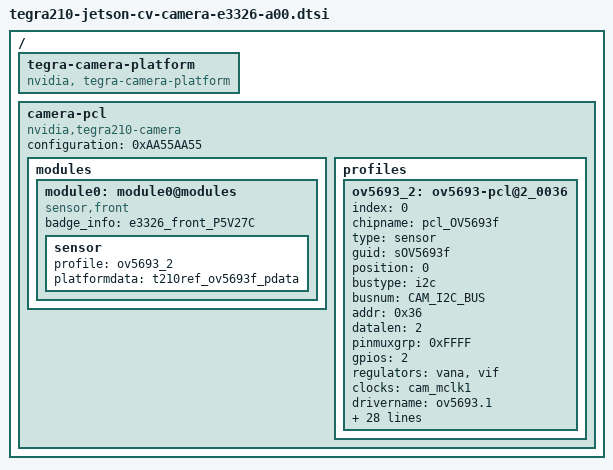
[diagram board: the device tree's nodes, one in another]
/*
 * Copyright (c) 2015, NVIDIA CORPORATION.  All rights reserved.
 *
 * This program is free software; you can redistribute it and/or modify
 * it under the terms of the GNU General Public License as published by
 * the Free Software Foundation; either version 2 of the License, or
 * (at your option) any later version.
 *
 * This program is distributed in the hope that it will be useful, but WITHOUT
 * ANY WARRANTY; without even the implied warranty of MERCHANTABILITY or
 * FITNESS FOR A PARTICULAR PURPOSE.  See the GNU General Public License for
 * more details.
 *
 * You should have received a copy of the GNU General Public License
 * along with this program.  If not, see <http://www.gnu.org/licenses/>.
 */

#include <dt-bindings/media/camera.h>
#include <dt-bindings/platform/t210/t210.h>

#define CAM_I2C_BUS	6

#define CAM0_RST_L	TEGRA_GPIO(S, 4)
#define CAM0_PWDN		TEGRA_GPIO(S, 7)
#define CAM1_RST_L	TEGRA_GPIO(S, 5)
#define CAM1_PWDN		TEGRA_GPIO(T, 0)

/* camera control gpio definitions */

/ {
	tegra-camera-platform {
		compatible = "nvidia, tegra-camera-platform";
	};

	camera-pcl {
		compatible = "nvidia,tegra210-camera", "simple-bus";
		configuration = <0xAA55AA55>;

		modules {
			module0: module0@modules {
				compatible = "sensor,front";
				badge_info = "e3326_front_P5V27C";

				sensor {
					profile = <&ov5693_2>;
					platformdata = "t210ref_ov5693f_pdata";
				};
			};
		};

		profiles {
			ov5693_2: ov5693-pcl@2_0036 {
				index = <0>;
				chipname = "pcl_OV5693f";
				type = "sensor";
				guid = "sOV5693f";
				position = <0>;
				bustype = "i2c";
				busnum = <CAM_I2C_BUS>;
				addr = <0x36>;
				datalen = <2>;
				pinmuxgrp = <0xFFFF>;
				gpios = <2>;
				regulators = "vana", "vif";
				clocks = "cam_mclk1";
				drivername = "ov5693.1";
				devid = <0x5693>;
				poweron = <
					CAMERA_IND_CLK_SET(10000)
					CAMERA_GPIO_CLR(CAM0_PWDN)
					CAMERA_GPIO_CLR(CAM0_RST_L)
					CAMERA_WAITMS(1)
					CAMERA_REGULATOR_ON(0)
					CAMERA_REGULATOR_ON(1)
					CAMERA_WAITMS(1)
					CAMERA_GPIO_SET(CAM0_PWDN)
					CAMERA_GPIO_SET(CAM0_RST_L)
					CAMERA_WAITMS(10)
					CAMERA_END
					>;
				poweroff = <
					CAMERA_IND_CLK_CLR
					CAMERA_GPIO_CLR(CAM0_PWDN)
					CAMERA_GPIO_CLR(CAM0_RST_L)
					CAMERA_WAITUS(10)
					CAMERA_REGULATOR_OFF(1)
					CAMERA_REGULATOR_OFF(0)
					CAMERA_END
					>;
				/* sensor capabilities */
				cap-version = <0x34340002>;
				cap-identifier = "OV5693.1";
				cap-sensor_nvc_interface = <5>;
				cap-pixel_types = <0x101>;
				cap-orientation = <1>;
				cap-direction = <1>;
				cap-initial_clock_rate_khz = <6000>;
				cap-h_sync_edge = <0>;
				cap-v_sync_edge = <0>;
				cap-mclk_on_vgp0 = <0>;
				cap-csi_port = <1>;
				cap-data_lanes = <2>;
				cap-virtual_channel_id = <0>;
				cap-discontinuous_clk_mode = <0>;
				cap-cil_threshold_settle = <0>;
				cap-min_blank_time_width = <16>;
				cap-min_blank_time_height = <16>;
				cap-preferred_mode_index = <0>;
				cap-external_clock_khz_0 = <24000>;
				cap-clock_multiplier_0 = <8000000>;
				cap-external_clock_khz_1 = <0>;
				cap-clock_multiplier_1 = <0>;
				cap-hdr-enabled;
			};
		};
	};
};
